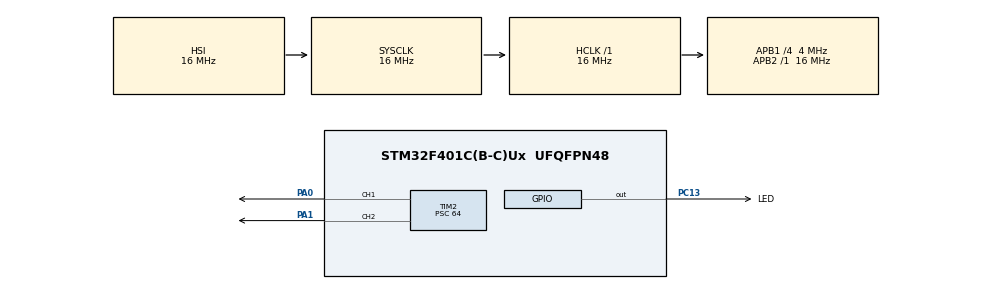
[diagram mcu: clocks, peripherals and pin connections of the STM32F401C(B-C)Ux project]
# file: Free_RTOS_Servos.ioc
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FREERTOS.Tasks01=Servo01,24,128,StartServo01,Default,NULL,Dynamic,NULL,NULL;Servo02,16,128,StartServo02,Default,NULL,Dynamic,NULL,NULL;StopServos,32,128,StartStopServos,Default,NULL,Dynamic,NULL,NULL
FREERTOS.configUSE_NEWLIB_REENTRANT=1
Mcu.Family=STM32F4
Mcu.Name=STM32F401C(B-C)Ux
Mcu.Package=UFQFPN48
NVIC.PriorityGroup=NVIC_PRIORITYGROUP_4
NVIC.TIM5_IRQn=true\:15\:0\:false\:false\:true\:false\:false\:true\:true
NVIC.TimeBase=TIM5_IRQn
NVIC.TimeBaseIP=TIM5
PA0-WKUP.Signal=S_TIM2_CH1_ETR
PA1.Signal=S_TIM2_CH2
PC13-ANTI_TAMP.GPIO_Label=LED
PC13-ANTI_TAMP.Signal=GPIO_Output
ProjectManager.HeapSize=0x200
ProjectManager.StackSize=0x400
ProjectManager.TargetToolchain=STM32CubeIDE
RCC.AHBFreq_Value=16000000
RCC.APB1CLKDivider=RCC_HCLK_DIV4
RCC.APB1Freq_Value=4000000
RCC.APB1TimFreq_Value=8000000
RCC.APB2Freq_Value=16000000
RCC.CortexFreq_Value=16000000
RCC.HSE_VALUE=25000000
RCC.HSI_VALUE=16000000
RCC.LSE_VALUE=32768
RCC.SYSCLKFreq_VALUE=16000000
RCC.VCOOutputFreq_Value=192000000
SH.S_TIM2_CH1_ETR.0=TIM2_CH1,PWM Generation1 CH1
SH.S_TIM2_CH2.0=TIM2_CH2,PWM Generation2 CH2
TIM2.Channel-PWM\ Generation1\ CH1=TIM_CHANNEL_1
TIM2.Channel-PWM\ Generation2\ CH2=TIM_CHANNEL_2
TIM2.Period=2499
TIM2.Prescaler=64
VP_FREERTOS_VS_CMSIS_V2.Mode=CMSIS_V2
VP_SYS_VS_tim5.Mode=TIM5
VP_TIM2_VS_ClockSourceINT.Mode=Internal
board=custom

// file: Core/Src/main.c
/* USER CODE BEGIN Header */
/**
  ******************************************************************************
  * @file           : main.c
  * @brief          : Main program body
  ******************************************************************************
  * @attention
  *
  * Copyright (c) 2023 STMicroelectronics.
  * All rights reserved.
  *
  * This software is licensed under terms that can be found in the LICENSE file
  * in the root directory of this software component.
  * If no LICENSE file comes with this software, it is provided AS-IS.
  *
  ******************************************************************************
  */
/* USER CODE END Header */
#include "main.h"
#include "cmsis_os.h"

TIM_HandleTypeDef htim2;

/* Definitions for Servo01 */
osThreadId_t Servo01Handle;
const osThreadAttr_t Servo01_attributes = {
  .name = "Servo01",
  .stack_size = 128 * 4,
  .priority = (osPriority_t) osPriorityNormal,
};
/* Definitions for Servo02 */
osThreadId_t Servo02Handle;
const osThreadAttr_t Servo02_attributes = {
  .name = "Servo02",
  .stack_size = 128 * 4,
  .priority = (osPriority_t) osPriorityBelowNormal,
};
/* Definitions for StopServos */
osThreadId_t StopServosHandle;
const osThreadAttr_t StopServos_attributes = {
  .name = "StopServos",
  .stack_size = 128 * 4,
  .priority = (osPriority_t) osPriorityAboveNormal,
};
/* USER CODE BEGIN PV */
int servo_1_stop = 0, servo_2_stop = 0;
float ang[2];
/* USER CODE END PV */

void SystemClock_Config(void);
static void MX_GPIO_Init(void);
static void MX_TIM2_Init(void);
void StartServo01(void *argument);
void StartServo02(void *argument);
void StartStopServos(void *argument);

int main(void)
{

  /* MCU Configuration--------------------------------------------------------*/

  /* Reset of all peripherals, Initializes the Flash interface and the Systick. */
  HAL_Init();

  /* Configure the system clock */
  SystemClock_Config();

  /* Initialize all configured peripherals */
  MX_GPIO_Init();
  MX_TIM2_Init();
  /* USER CODE BEGIN 2 */
  HAL_TIM_PWM_Start(&htim2, TIM_CHANNEL_1);
  HAL_TIM_PWM_Start(&htim2, TIM_CHANNEL_2);
  TIM2->CCR1 = 60;
  TIM2->CCR2 = 60;
  /* USER CODE END 2 */

  /* Init scheduler */
  osKernelInitialize();

  /* Create the thread(s) */
  /* creation of Servo01 */
  Servo01Handle = osThreadNew(StartServo01, NULL, &Servo01_attributes);

  /* creation of Servo02 */
  Servo02Handle = osThreadNew(StartServo02, NULL, &Servo02_attributes);

  /* creation of StopServos */
  StopServosHandle = osThreadNew(StartStopServos, NULL, &StopServos_attributes);

  /* Start scheduler */
  osKernelStart();
  /* We should never get here as control is now taken by the scheduler */
  /* Infinite loop */
  while (1)
  {

  }
}

void SystemClock_Config(void)
{
  RCC_OscInitTypeDef RCC_OscInitStruct = {0};
  RCC_ClkInitTypeDef RCC_ClkInitStruct = {0};

  /** Configure the main internal regulator output voltage
  */
  __HAL_RCC_PWR_CLK_ENABLE();
  __HAL_PWR_VOLTAGESCALING_CONFIG(PWR_REGULATOR_VOLTAGE_SCALE2);

  /** Initializes the RCC Oscillators according to the specified parameters
  * in the RCC_OscInitTypeDef structure.
  */
  RCC_OscInitStruct.OscillatorType = RCC_OSCILLATORTYPE_HSI;
  RCC_OscInitStruct.HSIState = RCC_HSI_ON;
  RCC_OscInitStruct.HSICalibrationValue = RCC_HSICALIBRATION_DEFAULT;
  RCC_OscInitStruct.PLL.PLLState = RCC_PLL_NONE;
  if (HAL_RCC_OscConfig(&RCC_OscInitStruct) != HAL_OK)
  {
    Error_Handler();
  }

  /** Initializes the CPU, AHB and APB buses clocks
  */
  RCC_ClkInitStruct.ClockType = RCC_CLOCKTYPE_HCLK|RCC_CLOCKTYPE_SYSCLK
                              |RCC_CLOCKTYPE_PCLK1|RCC_CLOCKTYPE_PCLK2;
  RCC_ClkInitStruct.SYSCLKSource = RCC_SYSCLKSOURCE_HSI;
  RCC_ClkInitStruct.AHBCLKDivider = RCC_SYSCLK_DIV1;
  RCC_ClkInitStruct.APB1CLKDivider = RCC_HCLK_DIV4;
  RCC_ClkInitStruct.APB2CLKDivider = RCC_HCLK_DIV1;

  if (HAL_RCC_ClockConfig(&RCC_ClkInitStruct, FLASH_LATENCY_0) != HAL_OK)
  {
    Error_Handler();
  }
}

static void MX_TIM2_Init(void)
{

  TIM_ClockConfigTypeDef sClockSourceConfig = {0};
  TIM_MasterConfigTypeDef sMasterConfig = {0};
  TIM_OC_InitTypeDef sConfigOC = {0};

  htim2.Instance = TIM2;
  htim2.Init.Prescaler = 64;
  htim2.Init.CounterMode = TIM_COUNTERMODE_UP;
  htim2.Init.Period = 2499;
  htim2.Init.ClockDivision = TIM_CLOCKDIVISION_DIV1;
  htim2.Init.AutoReloadPreload = TIM_AUTORELOAD_PRELOAD_DISABLE;
  if (HAL_TIM_Base_Init(&htim2) != HAL_OK)
  {
    Error_Handler();
  }
  sClockSourceConfig.ClockSource = TIM_CLOCKSOURCE_INTERNAL;
  if (HAL_TIM_ConfigClockSource(&htim2, &sClockSourceConfig) != HAL_OK)
  {
    Error_Handler();
  }
  if (HAL_TIM_PWM_Init(&htim2) != HAL_OK)
  {
    Error_Handler();
  }
  sMasterConfig.MasterOutputTrigger = TIM_TRGO_RESET;
  sMasterConfig.MasterSlaveMode = TIM_MASTERSLAVEMODE_DISABLE;
  if (HAL_TIMEx_MasterConfigSynchronization(&htim2, &sMasterConfig) != HAL_OK)
  {
    Error_Handler();
  }
  sConfigOC.OCMode = TIM_OCMODE_PWM1;
  sConfigOC.Pulse = 0;
  sConfigOC.OCPolarity = TIM_OCPOLARITY_HIGH;
  sConfigOC.OCFastMode = TIM_OCFAST_DISABLE;
  if (HAL_TIM_PWM_ConfigChannel(&htim2, &sConfigOC, TIM_CHANNEL_1) != HAL_OK)
  {
    Error_Handler();
  }
  if (HAL_TIM_PWM_ConfigChannel(&htim2, &sConfigOC, TIM_CHANNEL_2) != HAL_OK)
  {
    Error_Handler();
  }
  HAL_TIM_MspPostInit(&htim2);

}

static void MX_GPIO_Init(void)
{
  GPIO_InitTypeDef GPIO_InitStruct = {0};

  /* GPIO Ports Clock Enable */
  __HAL_RCC_GPIOC_CLK_ENABLE();
  __HAL_RCC_GPIOA_CLK_ENABLE();

  /*Configure GPIO pin Output Level */
  HAL_GPIO_WritePin(LED_GPIO_Port, LED_Pin, GPIO_PIN_RESET);

  /*Configure GPIO pin : LED_Pin */
  GPIO_InitStruct.Pin = LED_Pin;
  GPIO_InitStruct.Mode = GPIO_MODE_OUTPUT_PP;
  GPIO_InitStruct.Pull = GPIO_NOPULL;
  GPIO_InitStruct.Speed = GPIO_SPEED_FREQ_LOW;
  HAL_GPIO_Init(LED_GPIO_Port, &GPIO_InitStruct);

}

/* USER CODE BEGIN 4 */
int funct_aux(){
	return TIM2->CCR1;
}
float pwm_to_ang(int n){
	if (n == 1){
		return (180.0/240.0)*((float)TIM2->CCR1 - 60);
	}
	if(n == 2){
		return (180.0/240.0)*((float)TIM2->CCR2 - 60);
	}
	return -1;
}
void move_servo_to(int n, int pwm){
	if (n == 1){
		TIM2->CCR1 = pwm;
	}
	else if(n == 2){
		TIM2->CCR2 = pwm;
	}
}
void move_servo_fw(int n){
	if (n == 1){
		TIM2->CCR1 += 1;
	}
	else if(n == 2){
		TIM2->CCR2 += 1;
	}
}
void move_servo_bw(int n){
	if (n == 1){
		TIM2->CCR1 -= 1;
	}
	else if(n == 2){
		TIM2->CCR2 -= 1;
	}
}

/* USER CODE END 4 */

void StartServo01(void *argument)
{
  /* USER CODE BEGIN 5 */
  /* Infinite loop */
  for(;;)
  {
	  if (servo_1_stop == 0){
		  move_servo_fw(1);
		  ang[0] = pwm_to_ang(1);
	  }
	  osDelay(100);
  }
  osThreadTerminate(NULL);
  /* USER CODE END 5 */
}

void StartServo02(void *argument)
{
  /* USER CODE BEGIN StartServo02 */
  /* Infinite loop */
  for(;;)
  {
	  if (servo_1_stop != 0 && servo_2_stop == 0){
		  move_servo_fw(2);
		  ang[1] = pwm_to_ang(2);
	  }
	  osDelay(100);
  }
  osThreadTerminate(NULL);
  /* USER CODE END StartServo02 */
}

void StartStopServos(void *argument)
{
  /* USER CODE BEGIN StartStopServos */
  /* Infinite loop */
  for(;;)
  {
	  if(TIM2->CCR1 > 200){
		  servo_1_stop = 1;
	  }
	  if(TIM2->CCR2 > 180){
	  		servo_2_stop = 1;
	  }
	  osDelay(100);
  }
  /* USER CODE END StartStopServos */
}

void HAL_TIM_PeriodElapsedCallback(TIM_HandleTypeDef *htim)
{
  if (htim->Instance == TIM5) {
    HAL_IncTick();
  }
}

void Error_Handler(void)
{
  __disable_irq();
  while (1)
  {
  }
}
